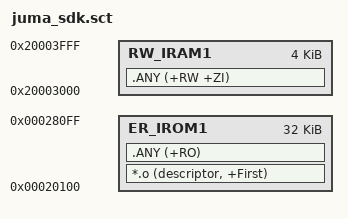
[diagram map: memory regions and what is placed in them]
; *************************************************************
; *** Scatter-Loading Description File generated by uVision ***
; *************************************************************

LR_IROM1 0x00020100 0x00008000  {    ; load region size_region
  ER_IROM1 0x00020100 0x00008000  {  ; load address = execution address
   *.o (descriptor, +First)
   .ANY (+RO)
  }
  RW_IRAM1 0x20003000 0x00001000  {  ; RW data
   .ANY (+RW +ZI)
  }
}
